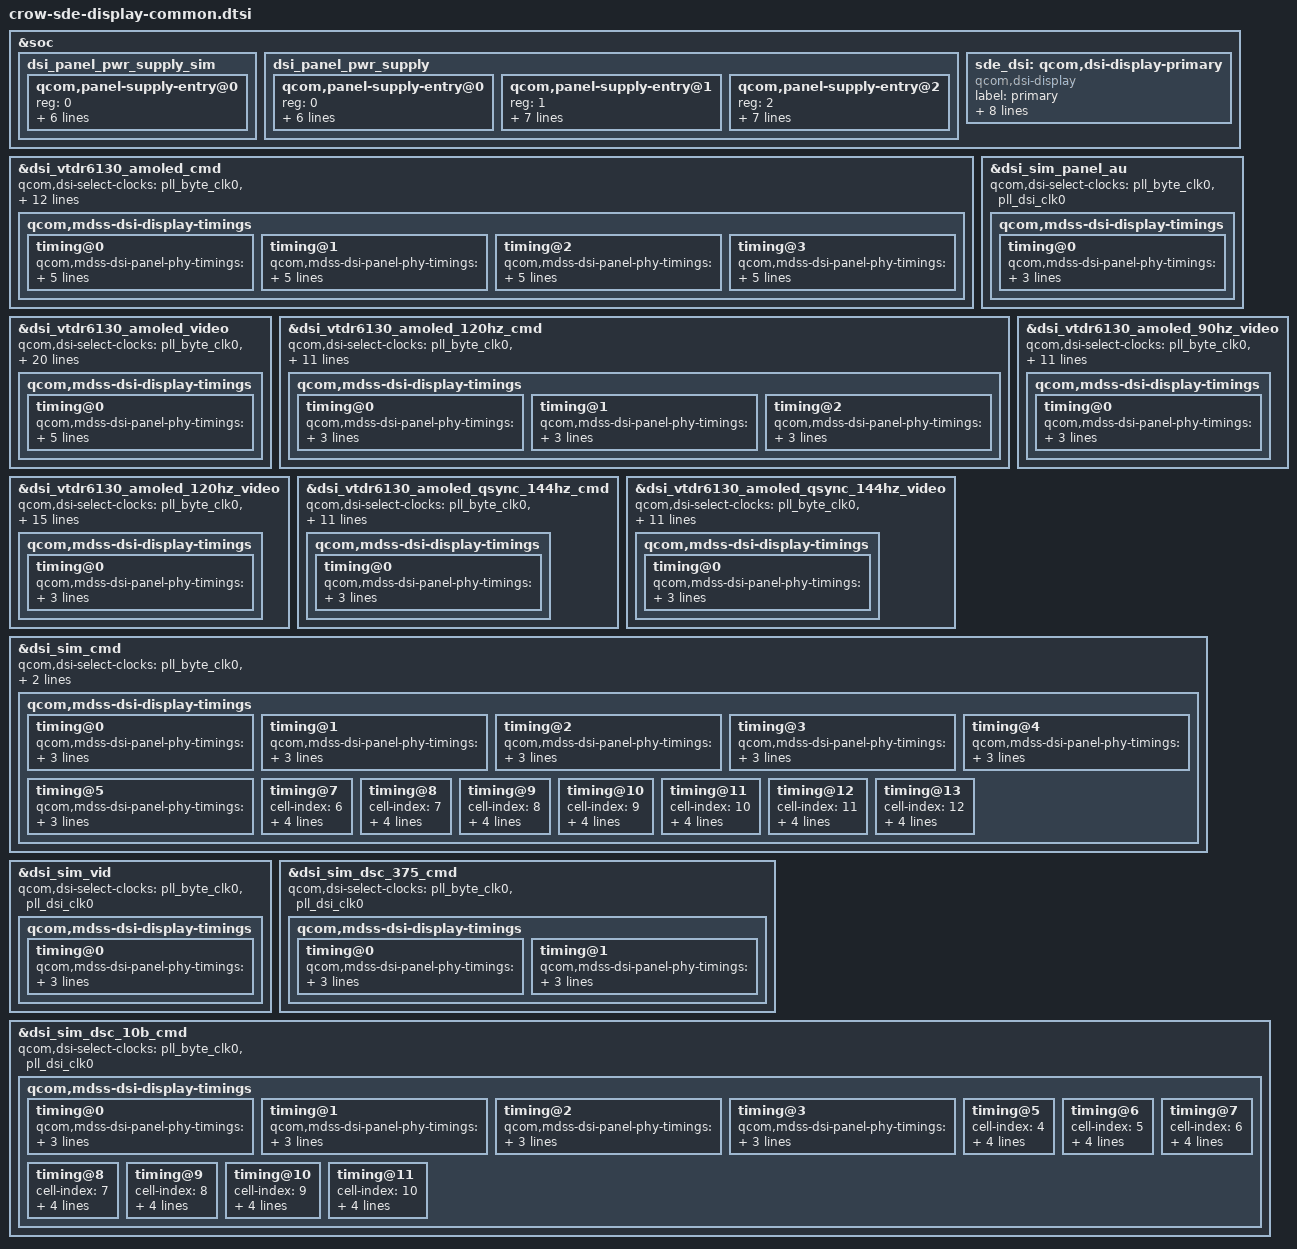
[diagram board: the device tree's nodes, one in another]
#include "dsi-panel-sim-cmd.dtsi"
#include "dsi-panel-sim-video.dtsi"
#include "dsi-panel-sim-dsc375-cmd.dtsi"
#include "dsi-panel-sim-dsc-10bit-cmd.dtsi"
#include "dsi-panel-sim-cmd-au.dtsi"
#include "dsi-panel-vtdr6130-dsc-fhd-plus-cmd.dtsi"
#include "dsi-panel-vtdr6130-dsc-fhd-plus-video.dtsi"
#include "dsi-panel-vtdr6130-qsync-dsc-fhd-plus-144hz-cmd.dtsi"
#include "dsi-panel-vtdr6130-qsync-dsc-fhd-plus-144hz-video.dtsi"
#include "dsi-panel-vtdr6130-dsc-fhd-plus-120hz-cmd.dtsi"
#include "dsi-panel-vtdr6130-dsc-fhd-plus-120hz-video.dtsi"
#include "dsi-panel-vtdr6130-dsc-fhd-plus-90hz-video.dtsi"

#include "crow-sde-display-pinctrl.dtsi"

&soc {
	dsi_panel_pwr_supply_sim: dsi_panel_pwr_supply_sim {
		#address-cells = <1>;
		#size-cells = <0>;

		qcom,panel-supply-entry@0 {
			reg = <0>;
			qcom,supply-name = "dummy";
			qcom,supply-min-voltage = <1800000>;
			qcom,supply-max-voltage = <1800000>;
			qcom,supply-enable-load = <200000>;
			qcom,supply-disable-load = <80>;
			qcom,supply-post-on-sleep = <20>;
		};
	};

	dsi_panel_pwr_supply: dsi_panel_pwr_supply {
		#address-cells = <1>;
		#size-cells = <0>;

		qcom,panel-supply-entry@0 {
			reg = <0>;
			qcom,supply-name = "vddio";
			qcom,supply-min-voltage = <1800000>;
			qcom,supply-max-voltage = <1800000>;
			qcom,supply-enable-load = <200000>;
			qcom,supply-disable-load = <80>;
			qcom,supply-post-on-sleep = <20>;
		};

		qcom,panel-supply-entry@1 {
			reg = <1>;
			qcom,supply-name = "vci";
			qcom,supply-min-voltage = <3000000>;
			qcom,supply-max-voltage = <3000000>;
			qcom,supply-enable-load = <10000>;
			qcom,supply-disable-load = <0>;
			qcom,supply-post-on-sleep = <1>;
			qcom,supply-post-off-sleep = <2>;
		};

		qcom,panel-supply-entry@2 {
			reg = <2>;
			qcom,supply-name = "vdd";
			qcom,supply-min-voltage = <1200000>;
			qcom,supply-max-voltage = <1200000>;
			qcom,supply-enable-load = <299000>;
			qcom,supply-disable-load = <0>;
			qcom,supply-post-on-sleep = <0>;
			qcom,supply-post-off-sleep = <2>;
		};
	};

	sde_dsi: qcom,dsi-display-primary {
		compatible = "qcom,dsi-display";
		label = "primary";

		qcom,dsi-ctrl = <&mdss_dsi0>;
		qcom,dsi-phy = <&mdss_dsi_phy0>;

		pinctrl-names = "panel_active", "panel_suspend";
		pinctrl-0 = <&sde_dsi_active &sde_te_active>;
		pinctrl-1 = <&sde_dsi_suspend &sde_te_suspend>;

		qcom,platform-te-gpio = <&tlmm 122 0>;
		qcom,panel-te-source = <0>;

		qcom,mdp = <&mdss_mdp>;
		qcom,demura-panel-id = <0x0122e700 0x00000471>;
	};

};

/* PHY TIMINGS REVISION YL with reduced margins */
&dsi_vtdr6130_amoled_cmd {
	qcom,dsi-select-clocks = "pll_byte_clk0", "pll_dsi_clk0";

	qcom,dsi-dyn-clk-enable;

	qcom,esd-check-enabled;
	qcom,mdss-dsi-panel-status-check-mode = "reg_read";
	qcom,mdss-dsi-panel-status-command = [06 01 00 01 00 00 01 0a];
	qcom,mdss-dsi-panel-status-command-state = "dsi_lp_mode";
	qcom,mdss-dsi-panel-status-value = <0x9c>;
	qcom,mdss-dsi-panel-status-read-length = <1>;

	qcom,mdss-dsi-panel-hdr-enabled;

	qcom,mdss-dsi-display-timings {
		timing@0 {
			qcom,mdss-dsi-panel-phy-timings = [00 1c 08 07 17 22 07
				07 08 02 04 00 19 0c];
			qcom,display-topology = <2 2 1>;
			qcom,default-topology-index = <0>;
			qcom,dsi-dyn-clk-list = <813936000 818175250 822414500>;
		};
		timing@1 {
			qcom,mdss-dsi-panel-phy-timings = [00 1c 08 07 17 22 07
				07 08 02 04 00 19 0c];
			qcom,display-topology = <2 2 1>;
			qcom,default-topology-index = <0>;
			qcom,dsi-dyn-clk-list = <813936000 818175250 822414500>;
		};
		timing@2 {
			qcom,mdss-dsi-panel-phy-timings = [00 1c 08 07 17 22 07
				07 08 02 04 00 19 0c];
			qcom,display-topology = <2 2 1>;
			qcom,default-topology-index = <0>;
			qcom,dsi-dyn-clk-list = <813936000 818175250 822414500>;
		};
		timing@3 {
			qcom,mdss-dsi-panel-phy-timings = [00 1c 08 07 17 22 07
				07 08 02 04 00 19 0c];
			qcom,display-topology = <2 2 1>;
			qcom,default-topology-index = <0>;
			qcom,dsi-dyn-clk-list = <813936000 818175250 822414500>;
		};
	};
};

&dsi_sim_panel_au {
	qcom,dsi-select-clocks = "pll_byte_clk0", "pll_dsi_clk0";
	qcom,mdss-dsi-display-timings {
		timing@0 {
			qcom,mdss-dsi-panel-phy-timings = [00 1c 08 07 17 22 07
				07 08 02 04 00 19 0c];
			qcom,display-topology = <2 2 1>;
			qcom,default-topology-index = <0>;
		};
	};
};

&dsi_vtdr6130_amoled_video {
	qcom,dsi-select-clocks = "pll_byte_clk0", "pll_dsi_clk0";

	qcom,dsi-supported-dfps-list = <144 120 90 60>;
	qcom,mdss-dsi-pan-enable-dynamic-fps;
	qcom,mdss-dsi-pan-fps-update = "dfps_immediate_porch_mode_vfp";

	qcom,dsi-dyn-clk-enable;
	qcom,dsi-dyn-clk-type = "constant-fps-adjust-hfp";

	qcom,qsync-enable;
	qcom,dsi-supported-qsync-min-fps-list = <80 70 60 50>;

	qcom,esd-check-enabled;
	qcom,mdss-dsi-panel-status-check-mode = "reg_read";
	qcom,mdss-dsi-panel-status-command = [06 01 00 01 00 00 01 0a];
	qcom,mdss-dsi-panel-status-command-state = "dsi_lp_mode";
	qcom,mdss-dsi-panel-status-value = <0x9c>;
	qcom,mdss-dsi-panel-status-read-length = <1>;

	qcom,mdss-dsi-panel-hdr-enabled;

	qcom,mdss-dsi-display-timings {
		timing@0 {
			qcom,mdss-dsi-panel-phy-timings = [00 1c 08 07 17 22 07
				07 08 02 04 00 19 0c];
			qcom,display-topology = <2 2 1>;
			qcom,default-topology-index = <0>;
			qcom,dsi-dyn-clk-list = <847480320 844537680 841595040>;
		};
	};
};

&dsi_vtdr6130_amoled_120hz_cmd {
	qcom,dsi-select-clocks = "pll_byte_clk0", "pll_dsi_clk0";

	qcom,esd-check-enabled;
	qcom,mdss-dsi-panel-status-check-mode = "reg_read";
	qcom,mdss-dsi-panel-status-command = [06 01 00 01 00 00 01 0a];
	qcom,mdss-dsi-panel-status-command-state = "dsi_lp_mode";
	qcom,mdss-dsi-panel-status-value = <0x9c>;
	qcom,mdss-dsi-panel-status-read-length = <1>;

	qcom,mdss-dsi-panel-hdr-enabled;

	qcom,mdss-dsi-display-timings {
		timing@0 {
			qcom,mdss-dsi-panel-phy-timings = [00 19 06 06 15 20 07
				06 07 02 04 00 16 0b];
			qcom,display-topology = <2 2 1>;
			qcom,default-topology-index = <0>;
		};

		timing@1 {
			qcom,mdss-dsi-panel-phy-timings = [00 19 06 06 15 20 07
				06 07 02 04 00 16 0b];
			qcom,display-topology = <2 2 1>;
			qcom,default-topology-index = <0>;
		};

		timing@2 {
			qcom,mdss-dsi-panel-phy-timings = [00 19 06 06 15 20 07
				06 07 02 04 00 16 0b];
			qcom,display-topology = <2 2 1>;
			qcom,default-topology-index = <0>;
		};
	};
};

&dsi_vtdr6130_amoled_120hz_video {
	qcom,dsi-select-clocks = "pll_byte_clk0", "pll_dsi_clk0";

	qcom,dsi-supported-dfps-list = <120 90 60>;
	qcom,mdss-dsi-pan-enable-dynamic-fps;
	qcom,mdss-dsi-pan-fps-update = "dfps_immediate_porch_mode_vfp";

	qcom,esd-check-enabled;
	qcom,mdss-dsi-panel-status-check-mode = "reg_read";
	qcom,mdss-dsi-panel-status-command = [06 01 00 01 00 00 01 0a];
	qcom,mdss-dsi-panel-status-command-state = "dsi_lp_mode";
	qcom,mdss-dsi-panel-status-value = <0x9c>;
	qcom,mdss-dsi-panel-status-read-length = <1>;

	qcom,mdss-dsi-panel-hdr-enabled;

	qcom,mdss-dsi-display-timings {
		timing@0 {
			qcom,mdss-dsi-panel-phy-timings = [00 19 06 06 15 14 07
				06 07 02 04 00 16 0b];
			qcom,display-topology = <2 2 1>;
			qcom,default-topology-index = <0>;
		};
	};
};

&dsi_vtdr6130_amoled_90hz_video {
	qcom,dsi-select-clocks = "pll_byte_clk0", "pll_dsi_clk0";

	qcom,esd-check-enabled;
	qcom,mdss-dsi-panel-status-check-mode = "reg_read";
	qcom,mdss-dsi-panel-status-command = [06 01 00 01 00 00 01 0a];
	qcom,mdss-dsi-panel-status-command-state = "dsi_lp_mode";
	qcom,mdss-dsi-panel-status-value = <0x9c>;
	qcom,mdss-dsi-panel-status-read-length = <1>;

	qcom,mdss-dsi-panel-hdr-enabled;

	qcom,mdss-dsi-display-timings {
		timing@0 {
			qcom,mdss-dsi-panel-phy-timings = [00 13 05 04 13 1e 05
				05 06 02 04 00 12 0a];
			qcom,display-topology = <2 2 1>;
			qcom,default-topology-index = <0>;
		};
	};
};

&dsi_vtdr6130_amoled_qsync_144hz_cmd {
	qcom,dsi-select-clocks = "pll_byte_clk0", "pll_dsi_clk0";

	qcom,esd-check-enabled;
	qcom,mdss-dsi-panel-status-check-mode = "reg_read";
	qcom,mdss-dsi-panel-status-command = [06 01 00 01 00 00 01 0a];
	qcom,mdss-dsi-panel-status-command-state = "dsi_lp_mode";
	qcom,mdss-dsi-panel-status-value = <0x9c>;
	qcom,mdss-dsi-panel-status-read-length = <1>;

	qcom,mdss-dsi-panel-hdr-enabled;

	qcom,mdss-dsi-display-timings {
		timing@0 {
			qcom,mdss-dsi-panel-phy-timings = [00 1c 08 07 17 22 07
				07 08 02 04 00 19 0c];
			qcom,display-topology = <2 2 1>;
			qcom,default-topology-index = <0>;
		};
	};
};

&dsi_vtdr6130_amoled_qsync_144hz_video {
	qcom,dsi-select-clocks = "pll_byte_clk0", "pll_dsi_clk0";

	qcom,esd-check-enabled;
	qcom,mdss-dsi-panel-status-check-mode = "reg_read";
	qcom,mdss-dsi-panel-status-command = [06 01 00 01 00 00 01 0a];
	qcom,mdss-dsi-panel-status-command-state = "dsi_lp_mode";
	qcom,mdss-dsi-panel-status-value = <0x9c>;
	qcom,mdss-dsi-panel-status-read-length = <1>;

	qcom,mdss-dsi-panel-hdr-enabled;

	qcom,mdss-dsi-display-timings {
		timing@0 {
			qcom,mdss-dsi-panel-phy-timings = [00 1c 08 07 17 22 07
				07 08 02 04 00 19 0c];
			qcom,display-topology = <2 2 1>;
			qcom,default-topology-index = <0>;
		};
	};
};

&dsi_sim_cmd {
	qcom,dsi-select-clocks = "pll_byte_clk0", "pll_dsi_clk0";
	qcom,poms-align-panel-vsync;
	qcom,mdss-dsi-display-timings {
		timing@0 { /* WQHD 60FPS cmd-vid mode*/
			qcom,mdss-dsi-panel-phy-timings = [00 1a 06 06 16 20 07
				07 07 02 04 00 16 0c];
			qcom,display-topology = <1 1 1>,
						<2 2 1>;
			qcom,default-topology-index = <1>;
		};

		timing@1 { /* WQHD 60FPS vid mode*/
			qcom,mdss-dsi-panel-phy-timings = [00 1a 06 06 16 20 07
				07 07 02 04 00 16 0c];
			qcom,display-topology = <1 1 1>,
						<2 2 1>;
			qcom,default-topology-index = <1>;
		};

		timing@2 { /* FHD+ 60FPS cmd mode*/
			qcom,mdss-dsi-panel-phy-timings = [00 25 0a 0a 1b 24 0a
				0a 0a 02 04 00 1f 0f];
			qcom,display-topology = <1 1 1>,
						<2 2 1>;
			qcom,default-topology-index = <1>;
		};

		timing@3 { /* HD 60FPS cmd mode */
			qcom,mdss-dsi-panel-phy-timings = [00 29 0a 0b 1b 26 0a
				0b 0a 02 04 00 21 10];
			qcom,display-topology = <1 1 1>,
						<2 2 1>;
			qcom,default-topology-index = <1>;
		};

		timing@4 { /* FHD+ 90FPS cmd mode*/
			qcom,mdss-dsi-panel-phy-timings = [00 39 0f 0e 21 2a 0e
				0f 0d 02 04 00 2d 13];
			qcom,display-topology = <1 1 1>,
						<2 2 1>;
			qcom,default-topology-index = <1>;
		};

		timing@5 { /* FHD+ 180 FPS cmd mode*/
			qcom,mdss-dsi-panel-phy-timings = [00 69 1d 1d 35 2f 1b
				1d 18 02 04 00 51 21];
			qcom,display-topology = <2 2 1>;
			qcom,default-topology-index = <0>;
		};

		/delete-node/ timing@6; /* FHD+ 240 FPS cmd mode*/

		timing@7 { /* FHD+ 120FPS cmd mode*/
			cell-index = <6>;
			qcom,mdss-dsi-panel-phy-timings = [00 4a 13 14 28 24 12
				14 11 02 04 00 39 18];
			qcom,display-topology = <1 1 1>,
						<2 2 1>;
			qcom,default-topology-index = <1>;
		};

		timing@8 { /* FHD+ 1FPS cmd mode*/
			cell-index = <7>;
			qcom,mdss-dsi-panel-phy-timings = [03 04 00 00 0d 18 01
				00 01 02 04 00 05 05];
			qcom,display-topology = <1 1 1>,
						<2 2 1>;
			qcom,default-topology-index = <1>;
		};

		timing@9 { /* FHD+ 5FPS cmd mode*/
			cell-index = <8>;
			qcom,mdss-dsi-panel-phy-timings = [03 06 00 00 0d 1a 01
				00 01 02 04 00 06 05];
			qcom,display-topology = <1 1 1>,
						<2 2 1>;
			qcom,default-topology-index = <1>;
		};

		timing@10 { /* FHD+ 10FPS cmd mode*/
			cell-index = <9>;
			qcom,mdss-dsi-panel-phy-timings = [03 07 00 01 0d 1a 01
				01 01 02 04 00 07 06];
			qcom,display-topology = <1 1 1>,
						<2 2 1>;
			qcom,default-topology-index = <1>;
		};

		timing@11 { /* FHD+ 24FPS cmd mode*/
			cell-index = <10>;
			qcom,mdss-dsi-panel-phy-timings = [00 09 01 01 0e 1b 02
				01 01 02 04 00 08 06];
			qcom,display-topology = <1 1 1>,
						<2 2 1>;
			qcom,default-topology-index = <1>;
		};

		timing@12 { /* FHD+ 30FPS cmd mode*/
			cell-index = <11>;
			qcom,mdss-dsi-panel-phy-timings = [00 0a 01 02 0e 1b 02
				02 01 02 04 00 09 07];
			qcom,display-topology = <1 1 1>,
						<2 2 1>;
			qcom,default-topology-index = <1>;
		};

		timing@13 { /* FHD+ 144FPS cmd mode*/
			cell-index = <12>;
			qcom,mdss-dsi-panel-phy-timings = [00 1a 06 06 16 20 07
				06 07 02 04 00 16 0b];
			qcom,display-topology = <1 1 1>,
						<2 2 1>;
			qcom,default-topology-index = <1>;
		};
	};
};

&dsi_sim_vid {
	qcom,dsi-select-clocks = "pll_byte_clk0", "pll_dsi_clk0";
	qcom,mdss-dsi-display-timings {
		timing@0 {
			qcom,mdss-dsi-panel-phy-timings = [01 05 01 01 03 03 01
				01 01 02 04 00 06 06];
			qcom,display-topology = <1 0 1>,
						<2 0 1>;
			qcom,default-topology-index = <0>;
		};
	};
};

&dsi_sim_dsc_375_cmd {
	qcom,dsi-select-clocks = "pll_byte_clk0", "pll_dsi_clk0";
	qcom,mdss-dsi-display-timings {
		timing@0 { /* 1080p */
			qcom,mdss-dsi-panel-phy-timings = [00 15 05 05 14 1f 05
				05 06 02 04 00 13 0a];
			qcom,display-topology = <1 1 1>;
			qcom,default-topology-index = <0>;
		};

		timing@1 { /* qhd */
			qcom,mdss-dsi-panel-phy-timings = [00 0c 02 02 10 1c 03
				03 02 02 04 00 0b 08];
			qcom,display-topology = <1 1 1>,
						<2 2 1>, /* dsc merge */
						<2 1 1>; /* 3d mux */
			qcom,default-topology-index = <0>;
		};
	};
};

&dsi_sim_dsc_10b_cmd {
	qcom,dsi-select-clocks = "pll_byte_clk0", "pll_dsi_clk0";
	qcom,mdss-dsi-display-timings {
		timing@0 { /* QHD 60fps */
			qcom,mdss-dsi-panel-phy-timings = [00 15 05 05 14 1f 05
				05 06 02 04 00 13 0a];
			qcom,display-topology = <1 1 1>,
						<2 2 1>, /* dsc merge */
						<2 1 1>; /* 3d mux */
			qcom,default-topology-index = <1>;
		};

		timing@1 { /* FHD+ 60fps cmd mode */
			qcom,mdss-dsi-panel-phy-timings = [00 0d 03 03 10 1d 03
				03 02 02 04 00 0c 08];
			qcom,display-topology = <1 1 1>,
						<2 2 1>, /* dsc merge */
						<2 1 1>; /* 3d mux */
			qcom,default-topology-index = <1>;
		};

		timing@2 { /* QHD 90fps */
			qcom,mdss-dsi-panel-phy-timings = [00 1d 08 07 17 22 08
				08 08 02 04 00 19 0d];
			qcom,display-topology = <1 1 1>,
						<2 2 1>, /* dsc merge */
						<2 1 1>; /* 3d mux */
			qcom,default-topology-index = <1>;
		};

		timing@3 { /* FHD+ 180FPS cmd mode*/
			qcom,mdss-dsi-panel-phy-timings = [00 1f 08 07 18 16 08
				08 08 02 04 00 1a 0d];
			qcom,display-topology = <2 2 1>;
			qcom,default-topology-index = <0>;
		};

		/delete-node/ timing@4; /* FHD+ 240FPS cmd mode*/

		timing@5 { /* FHD+ 120FPS cmd mode*/
			cell-index = <4>;
			qcom,mdss-dsi-panel-phy-timings = [00 16 05 05 14 13 06
				06 06 02 04 00 13 0b];
			qcom,display-topology = <2 2 1>;
			qcom,default-topology-index = <0>;
		};

		timing@6 { /* FHD+ 1FPS cmd mode*/
			cell-index = <5>;
			qcom,mdss-dsi-panel-phy-timings = [03 04 00 00 0d 18 01
				00 01 02 04 00 05 05];
			qcom,display-topology = <1 1 1>,
						<2 2 1>;
			qcom,default-topology-index = <1>;
		};

		timing@7 { /* FHD+ 10FPS cmd mode*/
			cell-index = <6>;
			qcom,mdss-dsi-panel-phy-timings = [03 07 00 01 0d 1a 01
				01 01 02 04 00 07 06];
			qcom,display-topology = <1 1 1>,
						<2 2 1>;
			qcom,default-topology-index = <1>;
		};

		timing@8 { /* FHD+ 24FPS cmd mode*/
			cell-index = <7>;
			qcom,mdss-dsi-panel-phy-timings = [00 09 01 01 0e 1b 02
				01 01 02 04 00 08 06];
			qcom,display-topology = <1 1 1>,
						<2 2 1>;
			qcom,default-topology-index = <1>;
		};

		timing@9 { /* FHD+ 30FPS cmd mode*/
			cell-index = <8>;
			qcom,mdss-dsi-panel-phy-timings = [00 0a 01 02 0e 1b 02
				02 01 02 04 00 09 07];
			qcom,display-topology = <1 1 1>,
						<2 2 1>;
			qcom,default-topology-index = <1>;
		};

		timing@10 { /* FHD+ 90FPS cmd mode*/
			cell-index = <9>;
			qcom,mdss-dsi-panel-phy-timings = [00 39 0f 0e 21 2a 0e
				0f 0d 02 04 00 2d 13];
			qcom,display-topology = <2 2 1>;
			qcom,default-topology-index = <0>;
		};

		timing@11 { /* FHD+ 144FPS cmd mode*/
			cell-index = <10>;
			qcom,mdss-dsi-panel-phy-timings = [00 1a 06 06 16 20 07
				06 07 02 04 00 16 0b];
			qcom,display-topology = <2 2 1>;
			qcom,default-topology-index = <0>;
		};
	};
};
